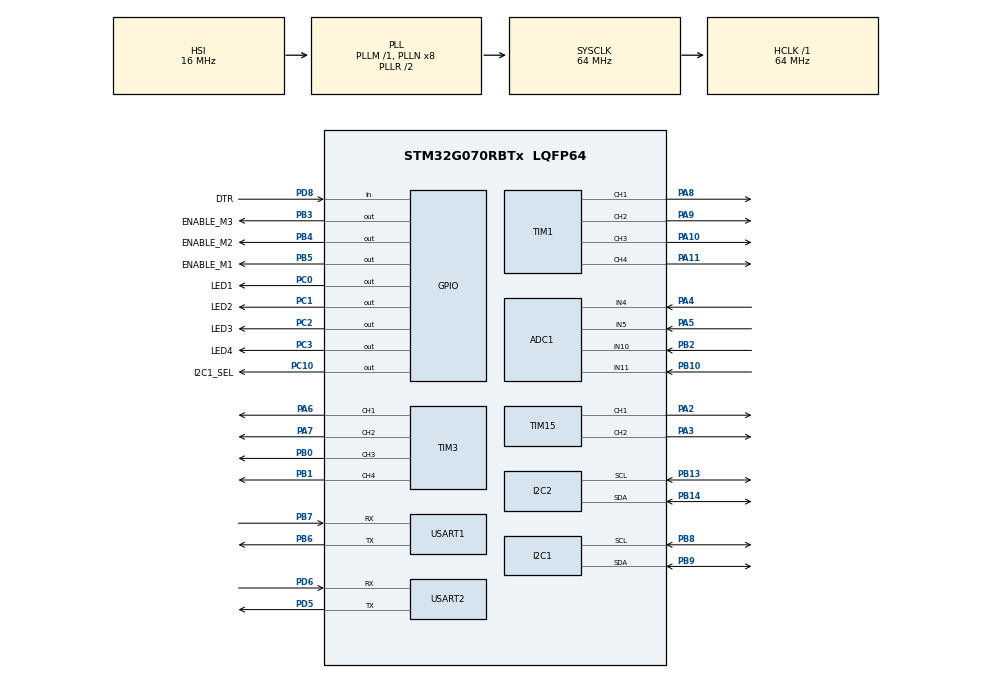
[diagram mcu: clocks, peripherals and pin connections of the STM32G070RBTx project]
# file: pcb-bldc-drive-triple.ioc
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ADC1.ClockPrescaler=ADC_CLOCK_ASYNC_DIV16
ADC1.ContinuousConvMode=ENABLE
ADC1.DMAContinuousRequests=ENABLE
ADC1.EOCSelection=ADC_EOC_SEQ_CONV
ADC1.NbrOfConversion=1
ADC1.NbrOfConversionFlag=0
ADC1.Overrun=ADC_OVR_DATA_OVERWRITTEN
ADC1.OversamplingMode=DISABLE
ADC1.SamplingTimeCommon1=ADC_SAMPLETIME_19CYCLES_5
ADC1.SelectedChannel=ADC_CHANNEL_4|ADC_CHANNEL_5|ADC_CHANNEL_10|ADC_CHANNEL_11
ADC1.Sequencer=NOT_FULLY_CONFIGURABLE
ADC1.master=1
Dma.ADC1.0.Direction=DMA_PERIPH_TO_MEMORY
Dma.ADC1.0.EventEnable=DISABLE
Dma.ADC1.0.Instance=DMA1_Channel1
Dma.ADC1.0.MemDataAlignment=DMA_MDATAALIGN_WORD
Dma.ADC1.0.MemInc=DMA_MINC_ENABLE
Dma.ADC1.0.Mode=DMA_CIRCULAR
Dma.ADC1.0.PeriphDataAlignment=DMA_PDATAALIGN_HALFWORD
Dma.ADC1.0.PeriphInc=DMA_PINC_DISABLE
Dma.ADC1.0.Polarity=HAL_DMAMUX_REQ_GEN_RISING
Dma.ADC1.0.Priority=DMA_PRIORITY_LOW
Dma.ADC1.0.RequestNumber=1
Dma.ADC1.0.SignalID=NONE
Dma.ADC1.0.SyncEnable=DISABLE
Dma.ADC1.0.SyncPolarity=HAL_DMAMUX_SYNC_NO_EVENT
Dma.ADC1.0.SyncRequestNumber=1
Dma.ADC1.0.SyncSignalID=NONE
Dma.Request0=ADC1
I2C1.Timing=0x10707DBC
I2C2.Timing=0x10707DBC
Mcu.Family=STM32G0
Mcu.Name=STM32G070RBTx
Mcu.Package=LQFP64
NVIC.I2C1_IRQn=true\:0\:0\:false\:false\:true\:true\:true\:true
NVIC.I2C2_IRQn=true\:0\:0\:false\:false\:true\:true\:true\:true
NVIC.TIM15_IRQn=true\:0\:0\:false\:false\:true\:true\:true\:true
NVIC.USART1_IRQn=true\:0\:0\:false\:false\:true\:true\:true\:true
NVIC.USART2_IRQn=true\:0\:0\:false\:false\:true\:true\:true\:true
PA10.Signal=S_TIM1_CH3
PA11\ [PA9].Signal=S_TIM1_CH4
PA13.Mode=Serial_Wire
PA13.Signal=SYS_SWDIO
PA14-BOOT0.Mode=Serial_Wire
PA14-BOOT0.Signal=SYS_SWCLK
PA2.Signal=S_TIM15_CH1
PA3.Signal=S_TIM15_CH2
PA4.Mode=IN4
PA4.Signal=ADC1_IN4
PA5.Mode=IN5
PA5.Signal=ADC1_IN5
PA6.Signal=S_TIM3_CH1
PA7.Signal=S_TIM3_CH2
PA8.Signal=S_TIM1_CH1
PA9.Signal=S_TIM1_CH2
PB0.Signal=S_TIM3_CH3
PB1.Signal=S_TIM3_CH4
PB10.Mode=IN11
PB10.Signal=ADC1_IN11
PB13.Mode=I2C
PB13.Signal=I2C2_SCL
PB14.Mode=I2C
PB14.Signal=I2C2_SDA
PB2.Mode=IN10
PB2.Signal=ADC1_IN10
PB3.GPIO_Label=ENABLE_M3
PB3.Signal=GPIO_Output
PB4.GPIO_Label=ENABLE_M2
PB4.Signal=GPIO_Output
PB5.GPIO_Label=ENABLE_M1
PB5.Signal=GPIO_Output
PB6.Mode=Asynchronous
PB6.Signal=USART1_TX
PB7.Mode=Asynchronous
PB7.Signal=USART1_RX
PB8.Mode=I2C
PB8.Signal=I2C1_SCL
PB9.Mode=I2C
PB9.Signal=I2C1_SDA
PC0.GPIO_Label=LED1
PC0.Signal=GPIO_Output
PC1.GPIO_Label=LED2
PC1.Signal=GPIO_Output
PC10.GPIO_Label=I2C1_SEL
PC10.Signal=GPIO_Output
PC2.GPIO_Label=LED3
PC2.Signal=GPIO_Output
PC3.GPIO_Label=LED4
PC3.Signal=GPIO_Output
PD5.Mode=Asynchronous
PD5.Signal=USART2_TX
PD6.Mode=Asynchronous
PD6.Signal=USART2_RX
PD8.GPIO_Label=DTR
PD8.Signal=GPIO_Input
ProjectManager.HeapSize=0x200
ProjectManager.StackSize=0x400
ProjectManager.TargetToolchain=STM32CubeIDE
RCC.ADCFreq_Value=64000000
RCC.AHBFreq_Value=64000000
RCC.CortexFreq_Value=64000000
RCC.EXTERNAL_CLOCK_VALUE=48000
RCC.HCLKFreq_Value=64000000
RCC.HSE_VALUE=8000000
RCC.HSI_VALUE=16000000
RCC.LSE_VALUE=32768
RCC.SYSCLKFreq_VALUE=64000000
RCC.SYSCLKSource=RCC_SYSCLKSOURCE_PLLCLK
RCC.VCOOutputFreq_Value=128000000
SH.S_TIM15_CH1.0=TIM15_CH1,PWM Generation1 CH1
SH.S_TIM15_CH2.0=TIM15_CH2,PWM Generation2 CH2
SH.S_TIM1_CH1.0=TIM1_CH1,PWM Generation1 CH1
SH.S_TIM1_CH2.0=TIM1_CH2,PWM Generation2 CH2
SH.S_TIM1_CH3.0=TIM1_CH3,PWM Generation3 CH3
SH.S_TIM1_CH4.0=TIM1_CH4,PWM Generation4 CH4
SH.S_TIM3_CH1.0=TIM3_CH1,PWM Generation1 CH1
SH.S_TIM3_CH2.0=TIM3_CH2,PWM Generation2 CH2
SH.S_TIM3_CH3.0=TIM3_CH3,PWM Generation3 CH3
SH.S_TIM3_CH4.0=TIM3_CH4,PWM Generation4 CH4
TIM1.AutoReloadPreload=TIM_AUTORELOAD_PRELOAD_ENABLE
TIM1.Channel-PWM\ Generation1\ CH1=TIM_CHANNEL_1
TIM1.Channel-PWM\ Generation2\ CH2=TIM_CHANNEL_2
TIM1.Channel-PWM\ Generation3\ CH3=TIM_CHANNEL_3
TIM1.Channel-PWM\ Generation4\ CH4=TIM_CHANNEL_4
TIM1.TIM_MasterOutputTrigger=TIM_TRGO_UPDATE
TIM1.TIM_MasterSlaveMode=TIM_MASTERSLAVEMODE_DISABLE
TIM15.AutoReloadPreload=TIM_AUTORELOAD_PRELOAD_ENABLE
TIM15.Channel-PWM\ Generation1\ CH1=TIM_CHANNEL_1
TIM15.Channel-PWM\ Generation2\ CH2=TIM_CHANNEL_2
TIM15.TIM_MasterOutputTrigger=TIM_TRGO_UPDATE
TIM3.AutoReloadPreload=TIM_AUTORELOAD_PRELOAD_ENABLE
TIM3.Channel-PWM\ Generation1\ CH1=TIM_CHANNEL_1
TIM3.Channel-PWM\ Generation2\ CH2=TIM_CHANNEL_2
TIM3.Channel-PWM\ Generation3\ CH3=TIM_CHANNEL_3
TIM3.Channel-PWM\ Generation4\ CH4=TIM_CHANNEL_4
USART1.VirtualMode-Asynchronous=VM_ASYNC
USART2.VirtualMode-Asynchronous=VM_ASYNC
VP_SYS_VS_DBSignals.Mode=DisableDeadBatterySignals
VP_TIM15_VS_ClockSourceINT.Mode=Internal
VP_TIM1_VS_ClockSourceINT.Mode=Internal
VP_TIM1_VS_ClockSourceITR.Mode=TriggerSource_ITR0
VP_TIM1_VS_ControllerModeCombinedResetTrigger.Mode=Combined_Reset_Trigger_Mode
VP_TIM3_VS_ClockSourceINT.Mode=Internal
VP_TIM3_VS_ClockSourceITR.Mode=TriggerSource_ITR2
VP_TIM3_VS_ControllerModeCombinedResetTrigger.Mode=Combined_Reset_Trigger_Mode
board=custom

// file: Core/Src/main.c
/* USER CODE BEGIN Header */
/**
  ******************************************************************************
  * @file           : main.c
  * @brief          : Main program body
  ******************************************************************************
  * @attention
  *
  * Copyright (c) 2024 STMicroelectronics.
  * All rights reserved.
  *
  * This software is licensed under terms that can be found in the LICENSE file
  * in the root directory of this software component.
  * If no LICENSE file comes with this software, it is provided AS-IS.
  *
  ******************************************************************************
  */
/* USER CODE END Header */
#include "main.h"

/* USER CODE BEGIN Includes */
#include "taskmanager.h"
/* USER CODE END Includes */

ADC_HandleTypeDef hadc1;
DMA_HandleTypeDef hdma_adc1;

I2C_HandleTypeDef hi2c1;
I2C_HandleTypeDef hi2c2;

TIM_HandleTypeDef htim1;
TIM_HandleTypeDef htim3;
TIM_HandleTypeDef htim15;

UART_HandleTypeDef huart1;
UART_HandleTypeDef huart2;

void SystemClock_Config(void);
static void MX_GPIO_Init(void);
static void MX_DMA_Init(void);
static void MX_ADC1_Init(void);
static void MX_TIM1_Init(void);
static void MX_TIM3_Init(void);
static void MX_TIM15_Init(void);
static void MX_I2C1_Init(void);
static void MX_I2C2_Init(void);
static void MX_USART1_UART_Init(void);
static void MX_USART2_UART_Init(void);

int main(void)
{

  /* MCU Configuration--------------------------------------------------------*/

  /* Reset of all peripherals, Initializes the Flash interface and the Systick. */
  HAL_Init();

  /* Configure the system clock */
  SystemClock_Config();

  /* Initialize all configured peripherals */
  MX_GPIO_Init();
  MX_DMA_Init();
  MX_ADC1_Init();
  MX_TIM1_Init();
  MX_TIM3_Init();
  MX_TIM15_Init();
  MX_I2C1_Init();
  MX_I2C2_Init();
  MX_USART1_UART_Init();
  MX_USART2_UART_Init();

  /* Infinite loop */
  /* USER CODE BEGIN WHILE */

  taskmanager_init();

  while (1)
  {
    /* USER CODE END WHILE */

  }
}

void SystemClock_Config(void)
{
  RCC_OscInitTypeDef RCC_OscInitStruct = {0};
  RCC_ClkInitTypeDef RCC_ClkInitStruct = {0};

  /** Configure the main internal regulator output voltage
  */
  HAL_PWREx_ControlVoltageScaling(PWR_REGULATOR_VOLTAGE_SCALE1);

  /** Initializes the RCC Oscillators according to the specified parameters
  * in the RCC_OscInitTypeDef structure.
  */
  RCC_OscInitStruct.OscillatorType = RCC_OSCILLATORTYPE_HSI;
  RCC_OscInitStruct.HSIState = RCC_HSI_ON;
  RCC_OscInitStruct.HSIDiv = RCC_HSI_DIV1;
  RCC_OscInitStruct.HSICalibrationValue = RCC_HSICALIBRATION_DEFAULT;
  RCC_OscInitStruct.PLL.PLLState = RCC_PLL_ON;
  RCC_OscInitStruct.PLL.PLLSource = RCC_PLLSOURCE_HSI;
  RCC_OscInitStruct.PLL.PLLM = RCC_PLLM_DIV1;
  RCC_OscInitStruct.PLL.PLLN = 8;
  RCC_OscInitStruct.PLL.PLLP = RCC_PLLP_DIV2;
  RCC_OscInitStruct.PLL.PLLR = RCC_PLLR_DIV2;
  if (HAL_RCC_OscConfig(&RCC_OscInitStruct) != HAL_OK)
  {
    Error_Handler();
  }

  /** Initializes the CPU, AHB and APB buses clocks
  */
  RCC_ClkInitStruct.ClockType = RCC_CLOCKTYPE_HCLK|RCC_CLOCKTYPE_SYSCLK
                              |RCC_CLOCKTYPE_PCLK1;
  RCC_ClkInitStruct.SYSCLKSource = RCC_SYSCLKSOURCE_PLLCLK;
  RCC_ClkInitStruct.AHBCLKDivider = RCC_SYSCLK_DIV1;
  RCC_ClkInitStruct.APB1CLKDivider = RCC_HCLK_DIV1;

  if (HAL_RCC_ClockConfig(&RCC_ClkInitStruct, FLASH_LATENCY_2) != HAL_OK)
  {
    Error_Handler();
  }
}

static void MX_ADC1_Init(void)
{

  ADC_ChannelConfTypeDef sConfig = {0};

  /** Configure the global features of the ADC (Clock, Resolution, Data Alignment and number of conversion)
  */
  hadc1.Instance = ADC1;
  hadc1.Init.ClockPrescaler = ADC_CLOCK_ASYNC_DIV16;
  hadc1.Init.Resolution = ADC_RESOLUTION_12B;
  hadc1.Init.DataAlign = ADC_DATAALIGN_RIGHT;
  hadc1.Init.ScanConvMode = ADC_SCAN_SEQ_FIXED;
  hadc1.Init.EOCSelection = ADC_EOC_SEQ_CONV;
  hadc1.Init.LowPowerAutoWait = DISABLE;
  hadc1.Init.LowPowerAutoPowerOff = DISABLE;
  hadc1.Init.ContinuousConvMode = ENABLE;
  hadc1.Init.NbrOfConversion = 1;
  hadc1.Init.ExternalTrigConv = ADC_SOFTWARE_START;
  hadc1.Init.ExternalTrigConvEdge = ADC_EXTERNALTRIGCONVEDGE_NONE;
  hadc1.Init.DMAContinuousRequests = ENABLE;
  hadc1.Init.Overrun = ADC_OVR_DATA_OVERWRITTEN;
  hadc1.Init.SamplingTimeCommon1 = ADC_SAMPLETIME_19CYCLES_5;
  hadc1.Init.OversamplingMode = DISABLE;
  hadc1.Init.TriggerFrequencyMode = ADC_TRIGGER_FREQ_HIGH;
  if (HAL_ADC_Init(&hadc1) != HAL_OK)
  {
    Error_Handler();
  }

  /** Configure Regular Channel
  */
  sConfig.Channel = ADC_CHANNEL_4;
  sConfig.Rank = ADC_RANK_CHANNEL_NUMBER;
  if (HAL_ADC_ConfigChannel(&hadc1, &sConfig) != HAL_OK)
  {
    Error_Handler();
  }

  /** Configure Regular Channel
  */
  sConfig.Channel = ADC_CHANNEL_5;
  if (HAL_ADC_ConfigChannel(&hadc1, &sConfig) != HAL_OK)
  {
    Error_Handler();
  }

  /** Configure Regular Channel
  */
  sConfig.Channel = ADC_CHANNEL_10;
  if (HAL_ADC_ConfigChannel(&hadc1, &sConfig) != HAL_OK)
  {
    Error_Handler();
  }

  /** Configure Regular Channel
  */
  sConfig.Channel = ADC_CHANNEL_11;
  if (HAL_ADC_ConfigChannel(&hadc1, &sConfig) != HAL_OK)
  {
    Error_Handler();
  }

}

static void MX_I2C1_Init(void)
{

  hi2c1.Instance = I2C1;
  hi2c1.Init.Timing = 0x10707DBC;
  hi2c1.Init.OwnAddress1 = 0;
  hi2c1.Init.AddressingMode = I2C_ADDRESSINGMODE_7BIT;
  hi2c1.Init.DualAddressMode = I2C_DUALADDRESS_DISABLE;
  hi2c1.Init.OwnAddress2 = 0;
  hi2c1.Init.OwnAddress2Masks = I2C_OA2_NOMASK;
  hi2c1.Init.GeneralCallMode = I2C_GENERALCALL_DISABLE;
  hi2c1.Init.NoStretchMode = I2C_NOSTRETCH_DISABLE;
  if (HAL_I2C_Init(&hi2c1) != HAL_OK)
  {
    Error_Handler();
  }

  /** Configure Analogue filter
  */
  if (HAL_I2CEx_ConfigAnalogFilter(&hi2c1, I2C_ANALOGFILTER_ENABLE) != HAL_OK)
  {
    Error_Handler();
  }

  /** Configure Digital filter
  */
  if (HAL_I2CEx_ConfigDigitalFilter(&hi2c1, 0) != HAL_OK)
  {
    Error_Handler();
  }

}

static void MX_I2C2_Init(void)
{

  hi2c2.Instance = I2C2;
  hi2c2.Init.Timing = 0x10707DBC;
  hi2c2.Init.OwnAddress1 = 0;
  hi2c2.Init.AddressingMode = I2C_ADDRESSINGMODE_7BIT;
  hi2c2.Init.DualAddressMode = I2C_DUALADDRESS_DISABLE;
  hi2c2.Init.OwnAddress2 = 0;
  hi2c2.Init.OwnAddress2Masks = I2C_OA2_NOMASK;
  hi2c2.Init.GeneralCallMode = I2C_GENERALCALL_DISABLE;
  hi2c2.Init.NoStretchMode = I2C_NOSTRETCH_DISABLE;
  if (HAL_I2C_Init(&hi2c2) != HAL_OK)
  {
    Error_Handler();
  }

  /** Configure Analogue filter
  */
  if (HAL_I2CEx_ConfigAnalogFilter(&hi2c2, I2C_ANALOGFILTER_ENABLE) != HAL_OK)
  {
    Error_Handler();
  }

  /** Configure Digital filter
  */
  if (HAL_I2CEx_ConfigDigitalFilter(&hi2c2, 0) != HAL_OK)
  {
    Error_Handler();
  }

}

static void MX_TIM1_Init(void)
{

  TIM_ClockConfigTypeDef sClockSourceConfig = {0};
  TIM_SlaveConfigTypeDef sSlaveConfig = {0};
  TIM_MasterConfigTypeDef sMasterConfig = {0};
  TIM_OC_InitTypeDef sConfigOC = {0};
  TIM_BreakDeadTimeConfigTypeDef sBreakDeadTimeConfig = {0};

  htim1.Instance = TIM1;
  htim1.Init.Prescaler = 0;
  htim1.Init.CounterMode = TIM_COUNTERMODE_UP;
  htim1.Init.Period = 65535;
  htim1.Init.ClockDivision = TIM_CLOCKDIVISION_DIV1;
  htim1.Init.RepetitionCounter = 0;
  htim1.Init.AutoReloadPreload = TIM_AUTORELOAD_PRELOAD_ENABLE;
  if (HAL_TIM_Base_Init(&htim1) != HAL_OK)
  {
    Error_Handler();
  }
  sClockSourceConfig.ClockSource = TIM_CLOCKSOURCE_INTERNAL;
  if (HAL_TIM_ConfigClockSource(&htim1, &sClockSourceConfig) != HAL_OK)
  {
    Error_Handler();
  }
  if (HAL_TIM_PWM_Init(&htim1) != HAL_OK)
  {
    Error_Handler();
  }
  sSlaveConfig.SlaveMode = TIM_SLAVEMODE_COMBINED_RESETTRIGGER;
  sSlaveConfig.InputTrigger = TIM_TS_ITR0;
  if (HAL_TIM_SlaveConfigSynchro(&htim1, &sSlaveConfig) != HAL_OK)
  {
    Error_Handler();
  }
  sMasterConfig.MasterOutputTrigger = TIM_TRGO_UPDATE;
  sMasterConfig.MasterOutputTrigger2 = TIM_TRGO2_RESET;
  sMasterConfig.MasterSlaveMode = TIM_MASTERSLAVEMODE_DISABLE;
  if (HAL_TIMEx_MasterConfigSynchronization(&htim1, &sMasterConfig) != HAL_OK)
  {
    Error_Handler();
  }
  sConfigOC.OCMode = TIM_OCMODE_PWM1;
  sConfigOC.Pulse = 0;
  sConfigOC.OCPolarity = TIM_OCPOLARITY_HIGH;
  sConfigOC.OCNPolarity = TIM_OCNPOLARITY_HIGH;
  sConfigOC.OCFastMode = TIM_OCFAST_DISABLE;
  sConfigOC.OCIdleState = TIM_OCIDLESTATE_RESET;
  sConfigOC.OCNIdleState = TIM_OCNIDLESTATE_RESET;
  if (HAL_TIM_PWM_ConfigChannel(&htim1, &sConfigOC, TIM_CHANNEL_1) != HAL_OK)
  {
    Error_Handler();
  }
  if (HAL_TIM_PWM_ConfigChannel(&htim1, &sConfigOC, TIM_CHANNEL_2) != HAL_OK)
  {
    Error_Handler();
  }
  if (HAL_TIM_PWM_ConfigChannel(&htim1, &sConfigOC, TIM_CHANNEL_3) != HAL_OK)
  {
    Error_Handler();
  }
  if (HAL_TIM_PWM_ConfigChannel(&htim1, &sConfigOC, TIM_CHANNEL_4) != HAL_OK)
  {
    Error_Handler();
  }
  sBreakDeadTimeConfig.OffStateRunMode = TIM_OSSR_DISABLE;
  sBreakDeadTimeConfig.OffStateIDLEMode = TIM_OSSI_DISABLE;
  sBreakDeadTimeConfig.LockLevel = TIM_LOCKLEVEL_OFF;
  sBreakDeadTimeConfig.DeadTime = 0;
  sBreakDeadTimeConfig.BreakState = TIM_BREAK_DISABLE;
  sBreakDeadTimeConfig.BreakPolarity = TIM_BREAKPOLARITY_HIGH;
  sBreakDeadTimeConfig.BreakFilter = 0;
  sBreakDeadTimeConfig.BreakAFMode = TIM_BREAK_AFMODE_INPUT;
  sBreakDeadTimeConfig.Break2State = TIM_BREAK2_DISABLE;
  sBreakDeadTimeConfig.Break2Polarity = TIM_BREAK2POLARITY_HIGH;
  sBreakDeadTimeConfig.Break2Filter = 0;
  sBreakDeadTimeConfig.Break2AFMode = TIM_BREAK_AFMODE_INPUT;
  sBreakDeadTimeConfig.AutomaticOutput = TIM_AUTOMATICOUTPUT_DISABLE;
  if (HAL_TIMEx_ConfigBreakDeadTime(&htim1, &sBreakDeadTimeConfig) != HAL_OK)
  {
    Error_Handler();
  }
  HAL_TIM_MspPostInit(&htim1);

}

static void MX_TIM3_Init(void)
{

  TIM_ClockConfigTypeDef sClockSourceConfig = {0};
  TIM_SlaveConfigTypeDef sSlaveConfig = {0};
  TIM_MasterConfigTypeDef sMasterConfig = {0};
  TIM_OC_InitTypeDef sConfigOC = {0};

  htim3.Instance = TIM3;
  htim3.Init.Prescaler = 0;
  htim3.Init.CounterMode = TIM_COUNTERMODE_UP;
  htim3.Init.Period = 65535;
  htim3.Init.ClockDivision = TIM_CLOCKDIVISION_DIV1;
  htim3.Init.AutoReloadPreload = TIM_AUTORELOAD_PRELOAD_ENABLE;
  if (HAL_TIM_Base_Init(&htim3) != HAL_OK)
  {
    Error_Handler();
  }
  sClockSourceConfig.ClockSource = TIM_CLOCKSOURCE_INTERNAL;
  if (HAL_TIM_ConfigClockSource(&htim3, &sClockSourceConfig) != HAL_OK)
  {
    Error_Handler();
  }
  if (HAL_TIM_PWM_Init(&htim3) != HAL_OK)
  {
    Error_Handler();
  }
  sSlaveConfig.SlaveMode = TIM_SLAVEMODE_COMBINED_RESETTRIGGER;
  sSlaveConfig.InputTrigger = TIM_TS_ITR2;
  if (HAL_TIM_SlaveConfigSynchro(&htim3, &sSlaveConfig) != HAL_OK)
  {
    Error_Handler();
  }
  sMasterConfig.MasterOutputTrigger = TIM_TRGO_RESET;
  sMasterConfig.MasterSlaveMode = TIM_MASTERSLAVEMODE_DISABLE;
  if (HAL_TIMEx_MasterConfigSynchronization(&htim3, &sMasterConfig) != HAL_OK)
  {
    Error_Handler();
  }
  sConfigOC.OCMode = TIM_OCMODE_PWM1;
  sConfigOC.Pulse = 0;
  sConfigOC.OCPolarity = TIM_OCPOLARITY_HIGH;
  sConfigOC.OCFastMode = TIM_OCFAST_DISABLE;
  if (HAL_TIM_PWM_ConfigChannel(&htim3, &sConfigOC, TIM_CHANNEL_1) != HAL_OK)
  {
    Error_Handler();
  }
  if (HAL_TIM_PWM_ConfigChannel(&htim3, &sConfigOC, TIM_CHANNEL_2) != HAL_OK)
  {
    Error_Handler();
  }
  if (HAL_TIM_PWM_ConfigChannel(&htim3, &sConfigOC, TIM_CHANNEL_3) != HAL_OK)
  {
    Error_Handler();
  }
  if (HAL_TIM_PWM_ConfigChannel(&htim3, &sConfigOC, TIM_CHANNEL_4) != HAL_OK)
  {
    Error_Handler();
  }
  HAL_TIM_MspPostInit(&htim3);

}

static void MX_TIM15_Init(void)
{

  TIM_ClockConfigTypeDef sClockSourceConfig = {0};
  TIM_MasterConfigTypeDef sMasterConfig = {0};
  TIM_OC_InitTypeDef sConfigOC = {0};
  TIM_BreakDeadTimeConfigTypeDef sBreakDeadTimeConfig = {0};

  htim15.Instance = TIM15;
  htim15.Init.Prescaler = 0;
  htim15.Init.CounterMode = TIM_COUNTERMODE_UP;
  htim15.Init.Period = 65535;
  htim15.Init.ClockDivision = TIM_CLOCKDIVISION_DIV1;
  htim15.Init.RepetitionCounter = 0;
  htim15.Init.AutoReloadPreload = TIM_AUTORELOAD_PRELOAD_ENABLE;
  if (HAL_TIM_Base_Init(&htim15) != HAL_OK)
  {
    Error_Handler();
  }
  sClockSourceConfig.ClockSource = TIM_CLOCKSOURCE_INTERNAL;
  if (HAL_TIM_ConfigClockSource(&htim15, &sClockSourceConfig) != HAL_OK)
  {
    Error_Handler();
  }
  if (HAL_TIM_PWM_Init(&htim15) != HAL_OK)
  {
    Error_Handler();
  }
  sMasterConfig.MasterOutputTrigger = TIM_TRGO_UPDATE;
  sMasterConfig.MasterSlaveMode = TIM_MASTERSLAVEMODE_DISABLE;
  if (HAL_TIMEx_MasterConfigSynchronization(&htim15, &sMasterConfig) != HAL_OK)
  {
    Error_Handler();
  }
  sConfigOC.OCMode = TIM_OCMODE_PWM1;
  sConfigOC.Pulse = 0;
  sConfigOC.OCPolarity = TIM_OCPOLARITY_HIGH;
  sConfigOC.OCNPolarity = TIM_OCNPOLARITY_HIGH;
  sConfigOC.OCFastMode = TIM_OCFAST_DISABLE;
  sConfigOC.OCIdleState = TIM_OCIDLESTATE_RESET;
  sConfigOC.OCNIdleState = TIM_OCNIDLESTATE_RESET;
  if (HAL_TIM_PWM_ConfigChannel(&htim15, &sConfigOC, TIM_CHANNEL_1) != HAL_OK)
  {
    Error_Handler();
  }
  if (HAL_TIM_PWM_ConfigChannel(&htim15, &sConfigOC, TIM_CHANNEL_2) != HAL_OK)
  {
    Error_Handler();
  }
  sBreakDeadTimeConfig.OffStateRunMode = TIM_OSSR_DISABLE;
  sBreakDeadTimeConfig.OffStateIDLEMode = TIM_OSSI_DISABLE;
  sBreakDeadTimeConfig.LockLevel = TIM_LOCKLEVEL_OFF;
  sBreakDeadTimeConfig.DeadTime = 0;
  sBreakDeadTimeConfig.BreakState = TIM_BREAK_DISABLE;
  sBreakDeadTimeConfig.BreakPolarity = TIM_BREAKPOLARITY_HIGH;
  sBreakDeadTimeConfig.BreakFilter = 0;
  sBreakDeadTimeConfig.AutomaticOutput = TIM_AUTOMATICOUTPUT_DISABLE;
  if (HAL_TIMEx_ConfigBreakDeadTime(&htim15, &sBreakDeadTimeConfig) != HAL_OK)
  {
    Error_Handler();
  }
  HAL_TIM_MspPostInit(&htim15);

}

static void MX_USART1_UART_Init(void)
{

  huart1.Instance = USART1;
  huart1.Init.BaudRate = 115200;
  huart1.Init.WordLength = UART_WORDLENGTH_8B;
  huart1.Init.StopBits = UART_STOPBITS_1;
  huart1.Init.Parity = UART_PARITY_NONE;
  huart1.Init.Mode = UART_MODE_TX_RX;
  huart1.Init.HwFlowCtl = UART_HWCONTROL_NONE;
  huart1.Init.OverSampling = UART_OVERSAMPLING_16;
  huart1.Init.OneBitSampling = UART_ONE_BIT_SAMPLE_DISABLE;
  huart1.Init.ClockPrescaler = UART_PRESCALER_DIV1;
  huart1.AdvancedInit.AdvFeatureInit = UART_ADVFEATURE_NO_INIT;
  if (HAL_UART_Init(&huart1) != HAL_OK)
  {
    Error_Handler();
  }
  if (HAL_UARTEx_SetTxFifoThreshold(&huart1, UART_TXFIFO_THRESHOLD_1_8) != HAL_OK)
  {
    Error_Handler();
  }
  if (HAL_UARTEx_SetRxFifoThreshold(&huart1, UART_RXFIFO_THRESHOLD_1_8) != HAL_OK)
  {
    Error_Handler();
  }
  if (HAL_UARTEx_DisableFifoMode(&huart1) != HAL_OK)
  {
    Error_Handler();
  }

}

static void MX_USART2_UART_Init(void)
{

  huart2.Instance = USART2;
  huart2.Init.BaudRate = 115200;
  huart2.Init.WordLength = UART_WORDLENGTH_8B;
  huart2.Init.StopBits = UART_STOPBITS_1;
  huart2.Init.Parity = UART_PARITY_NONE;
  huart2.Init.Mode = UART_MODE_TX_RX;
  huart2.Init.HwFlowCtl = UART_HWCONTROL_NONE;
  huart2.Init.OverSampling = UART_OVERSAMPLING_16;
  huart2.Init.OneBitSampling = UART_ONE_BIT_SAMPLE_DISABLE;
  huart2.Init.ClockPrescaler = UART_PRESCALER_DIV1;
  huart2.AdvancedInit.AdvFeatureInit = UART_ADVFEATURE_NO_INIT;
  if (HAL_UART_Init(&huart2) != HAL_OK)
  {
    Error_Handler();
  }
  if (HAL_UARTEx_SetTxFifoThreshold(&huart2, UART_TXFIFO_THRESHOLD_1_8) != HAL_OK)
  {
    Error_Handler();
  }
  if (HAL_UARTEx_SetRxFifoThreshold(&huart2, UART_RXFIFO_THRESHOLD_1_8) != HAL_OK)
  {
    Error_Handler();
  }
  if (HAL_UARTEx_DisableFifoMode(&huart2) != HAL_OK)
  {
    Error_Handler();
  }

}

static void MX_DMA_Init(void)
{

  /* DMA controller clock enable */
  __HAL_RCC_DMA1_CLK_ENABLE();

}

static void MX_GPIO_Init(void)
{
  GPIO_InitTypeDef GPIO_InitStruct = {0};

  /* GPIO Ports Clock Enable */
  __HAL_RCC_GPIOC_CLK_ENABLE();
  __HAL_RCC_GPIOA_CLK_ENABLE();
  __HAL_RCC_GPIOB_CLK_ENABLE();
  __HAL_RCC_GPIOD_CLK_ENABLE();

  /*Configure GPIO pin Output Level */
  HAL_GPIO_WritePin(GPIOC, LED1_Pin|LED2_Pin|LED3_Pin|LED4_Pin
                          |I2C1_SEL_Pin, GPIO_PIN_RESET);

  /*Configure GPIO pin Output Level */
  HAL_GPIO_WritePin(GPIOB, ENABLE_M3_Pin|ENABLE_M2_Pin|ENABLE_M1_Pin, GPIO_PIN_RESET);

  /*Configure GPIO pins : LED1_Pin LED2_Pin LED3_Pin LED4_Pin
                           I2C1_SEL_Pin */
  GPIO_InitStruct.Pin = LED1_Pin|LED2_Pin|LED3_Pin|LED4_Pin
                          |I2C1_SEL_Pin;
  GPIO_InitStruct.Mode = GPIO_MODE_OUTPUT_PP;
  GPIO_InitStruct.Pull = GPIO_NOPULL;
  GPIO_InitStruct.Speed = GPIO_SPEED_FREQ_LOW;
  HAL_GPIO_Init(GPIOC, &GPIO_InitStruct);

  /*Configure GPIO pin : DTR_Pin */
  GPIO_InitStruct.Pin = DTR_Pin;
  GPIO_InitStruct.Mode = GPIO_MODE_INPUT;
  GPIO_InitStruct.Pull = GPIO_NOPULL;
  HAL_GPIO_Init(DTR_GPIO_Port, &GPIO_InitStruct);

  /*Configure GPIO pins : ENABLE_M3_Pin ENABLE_M2_Pin ENABLE_M1_Pin */
  GPIO_InitStruct.Pin = ENABLE_M3_Pin|ENABLE_M2_Pin|ENABLE_M1_Pin;
  GPIO_InitStruct.Mode = GPIO_MODE_OUTPUT_PP;
  GPIO_InitStruct.Pull = GPIO_NOPULL;
  GPIO_InitStruct.Speed = GPIO_SPEED_FREQ_LOW;
  HAL_GPIO_Init(GPIOB, &GPIO_InitStruct);

}

void Error_Handler(void)
{
  __disable_irq();
  while (1)
  {
  }
}
